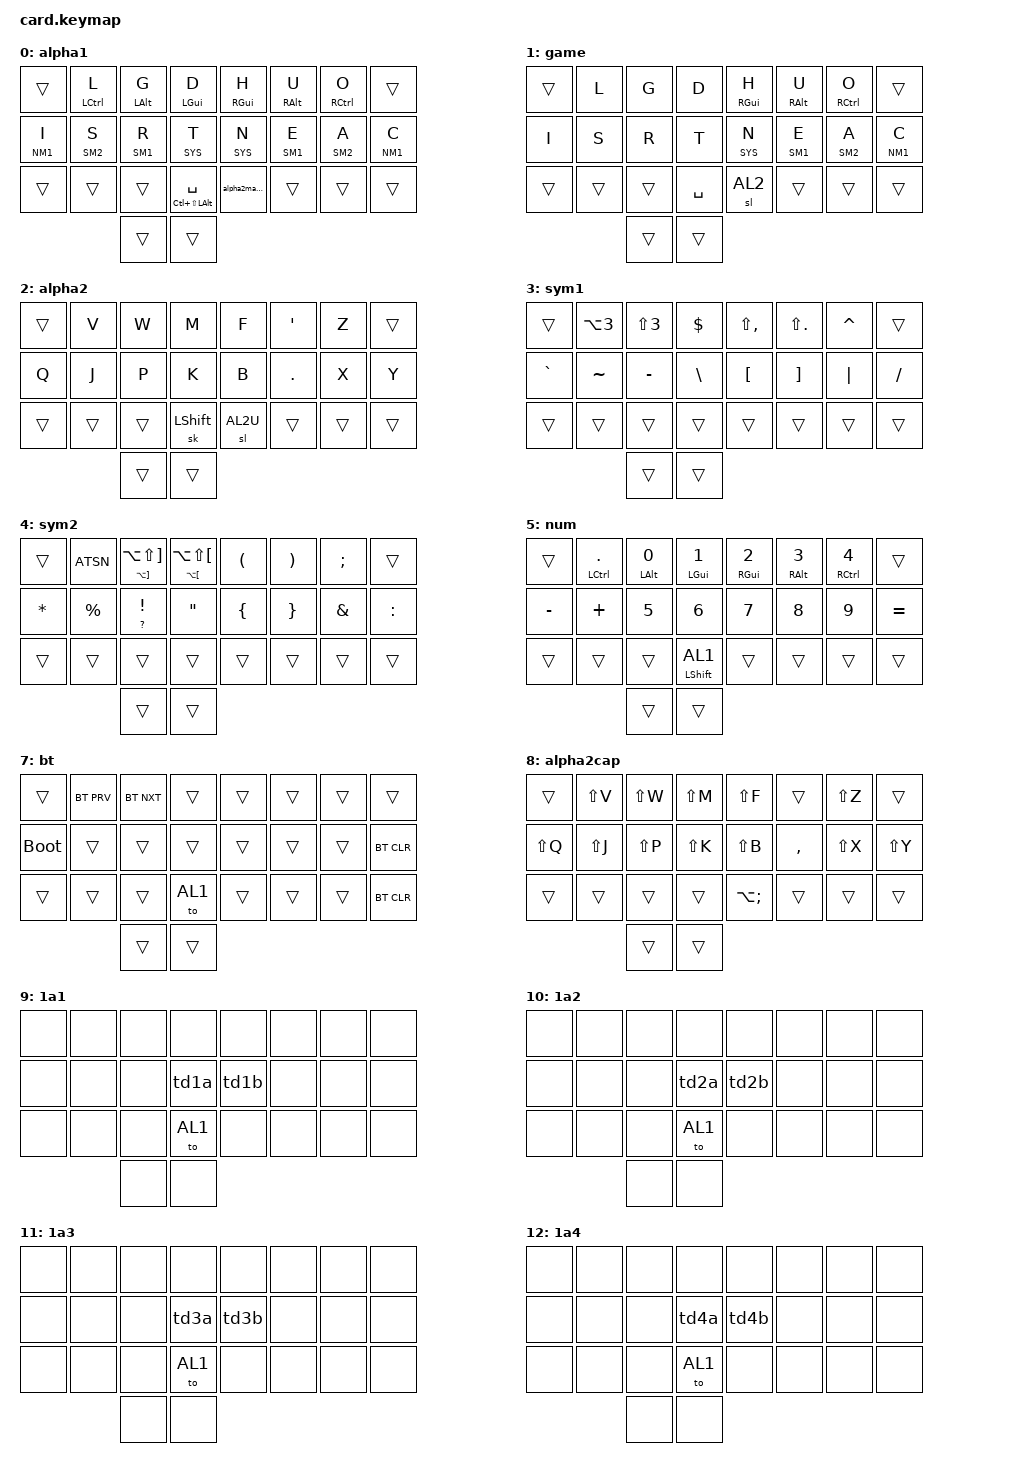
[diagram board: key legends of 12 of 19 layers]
/*
 * Copyright (c) 2020 The ZMK Contributors
 *
 * SPDX-License-Identifier: MIT
 */

#include <behaviors.dtsi>
#include <dt-bindings/zmk/keys.h>
#include <dt-bindings/zmk/bt.h>
#include <dt-bindings/zmk/mouse.h>



&mt {
    tapping-term-ms = <201>;
    flavor = "tap-preferred";
 };
&sk {
     release-after-ms = <2000>;
     quick-release;
 };
 
/* Layers */
#define AL1 0
#define GM 1
#define AL2 2
#define AL2U 8
#define SM1 3
#define SM2 4	
#define NM1 5	
#define SYS 6
#define BT 7	




#define AF1 9	
#define AF2 10	
#define AF3 11	
#define AF4 12	
#define AF5 13	
#define AF6 14	
#define AF7 15	
#define AF8 16	
#define AF9 17	
#define AF10 18	

/ { 
    combos {
        compatible = "zmk,combos";
        combo_game {
            timeout-ms = <30>;
	    key-positions = <2 3 4 5>;
            bindings = <&to GM>;
        };
        combo_1april {
            timeout-ms = <30>;
	    key-positions = <1 2 3>;
            bindings = <&to AF1>;
        };
        combo_sys {
            timeout-ms = <30>;
	    key-positions = <4 5 6>;
            bindings = <&to SYS>;
        };
        combo_caps {
            timeout-ms = <30>;
	    key-positions = <12 13 14>;
            bindings = <&caps_word>;
        };
        combo_bt  {
            timeout-ms = <10>;
            key-positions = <13 14>;
            bindings = <&to BT>;
	    layers = <SM1>; 
        };
        lalt {
            timeout-ms = <20>;
	    key-positions = <10 11>;
            bindings = <&kp LALT>; 
	    layers = <SYS>; 
        };
        lclk {
            timeout-ms = <20>;
	    key-positions = <12	13>;
            bindings = <&mkp LCLK>;
	    layers = <SYS>;
        };
        rclk {
            timeout-ms = <20>;
	    key-positions = <4 5>;
            bindings = <&mkp RCLK>;
	    layers = <SYS>;
        };


    };

    behaviors {
        hm: homerow_mods {
            compatible = "zmk,behavior-hold-tap";
            label = "HOMEROW_MODS";
            #binding-cells = <2>;
            tapping-term-ms = <300>;
            quick_tap_ms = <0>;
            flavor = "tap-preferred";
            bindings = <&kp>, <&kp>;
        };
        sr: shift_layer {
            compatible = "zmk,behavior-hold-tap";
            label = "SHIFT_LAYER";
            #binding-cells = <2>;
            tapping-term-ms = <300>;
            quick_tap_ms = <0>;
            flavor = "tap-preferred";
            bindings = <&kp>, <&to>;
	    retro-tap;
        };
        hl: homerow_layers {
            compatible = "zmk,behavior-hold-tap";
            label = "HOMEROW_LAYERS";
            #binding-cells = <2>;
            tapping-term-ms = <220>;
            quick_tap_ms = <0>;
            flavor = "tap-preferred";
            bindings = <&sl>, <&kp>;
        };
	td: tapdance {
            compatible = "zmk,behavior-hold-tap";
            label = "TAPDANCE";
            #binding-cells = <2>;
            tapping-term-ms = <190>;
            quick_tap_ms = <0>;
            flavor = "tap-preferred";
            bindings = <&kp>, <&kp>;
        };
	alpha2macro: behavior_macro_1 {
		compatible = "zmk,behavior-macro";
		label = "MACRO1";
		#binding-cells = <0>;
		bindings = < &sl AL2 >;
	};
	
	td1a: td1a {
            compatible = "zmk,behavior-tap-dance";
            label = "TD1A";
            #binding-cells = <0>;
            tapping-term-ms = <250>;
            bindings = <&sl AF2>, <&sl AF3>, <&sl AF4>;
        };
	td1b: td1b {
            compatible = "zmk,behavior-tap-dance";
            label = "TD1B";
            #binding-cells = <0>;
            tapping-term-ms = <250>;
            bindings = <&sl AF5>, <&sl AF6>, <&sl AF7>;
        };
	td2a: td2a {
            compatible = "zmk,behavior-tap-dance";
            label = "TD2A";
            #binding-cells = <0>;
            tapping-term-ms = <250>;
            bindings = <&kp A>, <&kp Y>, <&kp P>;
        };
	td2b: td2b {
            compatible = "zmk,behavior-tap-dance";
            label = "TD2B";
            #binding-cells = <0>;
            tapping-term-ms = <250>;
            bindings = <&kp E>, <&kp U>, <&kp X>;
        };
	td3a: td3a {
            compatible = "zmk,behavior-tap-dance";
            label = "TD3A";
            #binding-cells = <0>;
            tapping-term-ms = <250>;
            bindings = <&kp S>, <&kp V>, <&kp Q>;
        };
	td3b: td3b {
            compatible = "zmk,behavior-tap-dance";
            label = "TD3B";
            #binding-cells = <0>;
            tapping-term-ms = <250>;
            bindings = <&kp N>, <&kp R>, <&kp F>;
        };
	td4a: td4a {
            compatible = "zmk,behavior-tap-dance";
            label = "TD4A";
            #binding-cells = <0>;
            tapping-term-ms = <250>;
            bindings = <&kp K>, <&kp J>, <&kp Z>;
        };
	td4b: td4b {
            compatible = "zmk,behavior-tap-dance";
            label = "TD4B";
            #binding-cells = <0>;
            tapping-term-ms = <250>;
            bindings = <&kp H>, <&kp L>, <&kp W>;
        };
	td5a: td5a {
            compatible = "zmk,behavior-tap-dance";
            label = "TD5A";
            #binding-cells = <0>;
            tapping-term-ms = <250>;
            bindings = <&kp T>, <&kp M>, <&kp G>;
        };
	td5b: td5b {
            compatible = "zmk,behavior-tap-dance";
            label = "TD5B";
            #binding-cells = <0>;
            tapping-term-ms = <250>;
            bindings = <&kp I>, <&kp B>, <&kp Y>;
        };
	td6a: td6a {
            compatible = "zmk,behavior-tap-dance";
            label = "TD6A";
            #binding-cells = <0>;
            tapping-term-ms = <250>;
            bindings = <&kp O>, <&kp D>, <&kp QMARK>;
        };
	td6b: td6b {
            compatible = "zmk,behavior-tap-dance";
            label = "TD6B";
            #binding-cells = <0>;
            tapping-term-ms = <250>;
            bindings = <&kp BKSP>, <&kp RET>, <&kp TAB>;
        };
	td7a: td7a {
            compatible = "zmk,behavior-tap-dance";
            label = "TD7A";
            #binding-cells = <0>;
            tapping-term-ms = <250>;
            bindings = <&kp SPC>,<&kp ESC>, <&kp CAPS>;
        };
	td7b: td7b {
            compatible = "zmk,behavior-tap-dance";
            label = "TD7B";
            #binding-cells = <0>;
            tapping-term-ms = <250>;
            bindings = <&sl AF8>, <&sl AF9>, <&sl AF10>;
        };
	td8a: td8a {
            compatible = "zmk,behavior-tap-dance";
            label = "TD8A";
            #binding-cells = <0>;
            tapping-term-ms = <250>;
            bindings = <&kp N0>, <&kp N1>, <&kp N2>;
        };
	td8b: td8b {
            compatible = "zmk,behavior-tap-dance";
            label = "TD8B";
            #binding-cells = <0>;
            tapping-term-ms = <250>;
            bindings = <&kp N3>, <&kp N4>, <&kp N5>;
        };
	td9a: td9a {
            compatible = "zmk,behavior-tap-dance";
            label = "TD9A";
            #binding-cells = <0>;
            tapping-term-ms = <250>;
            bindings = <&kp N6>, <&kp N7>, <&kp N8>;
        };
	td9b: td9b {
            compatible = "zmk,behavior-tap-dance";
            label = "TD9B";
            #binding-cells = <0>;
            tapping-term-ms = <250>;
            bindings = <&kp N9>, <&kp MINUS>, <&kp DOT>;
        };
	td10a: td10a {
            compatible = "zmk,behavior-tap-dance";
            label = "TD10A";
            #binding-cells = <0>;
            tapping-term-ms = <250>;
            bindings = <&kp SQT>, <&kp DQT>, <&kp LBKT>;
        };
	td10b: td10b {
            compatible = "zmk,behavior-tap-dance";
            label = "TD11B";
            #binding-cells = <0>;
            tapping-term-ms = <250>;
            bindings = <&kp COMMA>, <&kp EXCL>, <&kp RBKT>;
        };
    };
       keymap {
                compatible = "zmk,keymap";
                
       		alpha1 {
		bindings = <
		&trans 		&hm LCTL L 	&hm LALT G 	&hm LGUI D		&hm RGUI H 	&hm RALT U    		&hm RCTL O	&trans  
		&hl NM1 I	&hl SM2 S	&hl SM1 R	&hl SYS T 	 	&hl SYS N    	&hl SM1 E   		&hl SM2 A 	&hl NM1 C
		&trans	 	&trans 		&trans 		&mt LC(LS(LALT)) SPC 	&alpha2macro	&trans 			&trans		&trans
								&trans	 		&trans
		>;
		};
       		game {
		bindings = <
		&trans 		&kp L 		&kp G 		&kp D			&hm RGUI H 	&hm RALT U    		&hm RCTL O	&trans  
		&kp I		&kp S		&kp R		&kp T 		 	&hl SYS N    	&hl SM1 E   		&hl SM2  A 	&hl NM1 C
		&trans	 	&trans 		&trans 		&kp SPC 		&sl AL2		&trans 			&trans		&trans
								&trans	 		&trans
		>;
		};
       		alpha2 {
		bindings = <
		&trans 	 	&kp V 		&kp W		&kp M	 	 	&kp F    	&kp SQT			&kp Z 		&trans
		&kp Q	 	&kp J 		&kp P		&kp K 			&kp B 		&kp DOT			&kp X		&kp Y 
		&trans	 	&trans 		&trans 		&sk LSHIFT 		&sl AL2U	&trans			&trans		&trans
								&trans	 		&trans
		>;
		};
		
       		sym1 {
		bindings = <
		&trans 		&kp LA(N3)   	&kp LS(N3)	&kp DLLR	    	&kp LS(COMMA)	&kp LS(DOT)		&kp CARET	&trans
		&kp GRAVE	&kp TILDE 	&kp MINUS      	&kp BSLH	 	&kp LBKT	&kp RBKT	 	&kp PIPE 	&kp SLASH
		&trans		&trans  	&trans		&trans  		&trans		&trans 			&trans  	&trans
							 	&trans		 	&trans
		>;
		};
		sym2 {
		bindings = <
		&trans		&kp ATSN	&td LA(RBKT) LA(LS(RBKT))	&td  LA(LBKT) LA(LS(LBKT))	&kp LPRN	&kp RPRN 	&kp SEMI 	&trans
		&kp STAR  	&kp PRCNT	&td QMARK EXCL       		&kp DQT   			&kp LBRC  	&kp RBRC	&kp AMPS	&kp COLON 
		&trans 		&trans 		&trans  			&trans 				&trans 		&trans 		&trans 		&trans   
						 				&trans				&trans

		>;
		};

		num {
		bindings = <
		&trans		&hm LCTL DOT 	&hm LALT N0	&hm LGUI N1 		&hm RGUI N2 	&hm RALT N3		&hm RCTL N4	&trans
		&kp MINUS	&kp PLUS 	&kp N5		&kp N6			&kp N7		&kp N8			&kp N9   	&kp EQUAL
		&trans  	&trans 		&trans		&sr LSHIFT AL1 		&trans 		&trans 			&trans  	&trans 
								&trans	 	 	&trans
		>;
		};

		sys {
		bindings = <
		&trans		 	&kp ESC			&kp LC(LS(TAB)) 	&kp RC(TAB)		&td LG(V) LG(C) 	&kp UP 		&td Q BKSP 			&trans
		&td LG(GRAVE) TAB	&td HOME DEL		&td END LG(LBKT) 	&kp LG(RBKT)		&td TAB LEFT  		&kp DOWN 	&td  LC(LG(LS(N4))) RIGHT 	&kp RET 
		&trans 			&trans 		 	&trans			&sr LSHIFT AL1 		&kp RGUI		&trans 		&trans				&trans 	   
									 		&trans	 		&trans
		>;
		};

		bt {
		bindings = <
		&trans		&bt BT_PRV	&bt BT_NXT	&trans 			&trans 	&trans	&trans	&trans
		&bootloader  	&trans 		&trans 		&trans 			&trans 	&trans 	&trans	&bt BT_CLR
		&trans 	 	&trans 		&trans		&to AL1			&trans  &trans  &trans 	&bt BT_CLR
						 		&trans			&trans
		>;
		};

       		alpha2cap {
		bindings = <
		&trans 	 	&kp LS(V)	&kp LS(W)	&kp LS(M) 	 	&kp LS(F)    	&trans		&kp LS(Z)	&trans 
		&kp LS(Q) 	&kp LS(J) 	&kp LS(P)	&kp LS(K)		&kp LS(B)	&kp COMMA	&kp LS(X)	&kp LS(Y) 
		&trans	 	&trans 		&trans 		&trans 			&kp LA(SEMI)	&trans		&trans		&trans
								&trans	 		&trans
		>;
		};








       		1a1 {
		bindings = <
		&none 	 	&none		&none 		&none			&none		&none		&none		&none
		&none 	 	&none		&none 		&td1a			&td1b		&none		&none		&none
		&none 	 	&none		&none 		&to AL1			&none		&none		&none		&none
								&none	 		&none
		>;
		};
       		1a2 {
		bindings = <
		&none 	 	&none		&none 		&none			&none		&none		&none		&none
		&none 	 	&none		&none 		&td2a 			&td2b		&none		&none		&none
		&none 	 	&none		&none 		&to AL1			&none		&none		&none		&none
								&none	 		&none
		>;
		};
       		1a3 {
		bindings = <
		&none 	 	&none		&none 		&none			&none		&none		&none		&none
		&none 	 	&none		&none 		&td3a			&td3b		&none		&none		&none
		&none 	 	&none		&none 		&to AL1			&none		&none		&none		&none
								&none	 		&none
		>;
		};
       		1a4 {
		bindings = <
		&none 	 	&none		&none 		&none			&none		&none		&none		&none
		&none 	 	&none		&none 		&td4a			&td4b		&none		&none		&none
		&none 	 	&none		&none 		&to AL1			&none		&none		&none		&none
								&none	 		&none
		>;
		};
       		1a5 {
		bindings = <
		&none 	 	&none		&none 		&none			&none		&none		&none		&none
		&none 	 	&none		&none 		&td5a			&td5b		&none		&none		&none
		&none 	 	&none		&none 		&to AL1			&none		&none		&none		&none
								&none	 		&none
		>;
		};
       		1a6 {
		bindings = <
		&none 	 	&none		&none 		&none			&none		&none		&none		&none
		&none 	 	&none		&none 		&td6a			&td6b		&none		&none		&none
		&none 	 	&none		&none 		&to AL1			&none		&none		&none		&none
								&none	 		&none
		>;
		};
       		1a7 {
		bindings = <
		&none 	 	&none		&none 		&none			&none		&none		&none		&none
		&none 	 	&none		&none 		&td7a			&td7b		&none		&none		&none
		&none 	 	&none		&none 		&to AL1			&none		&none		&none		&none
								&none	 		&none
		>;
		};
       		1a8 {
		bindings = <
		&none 	 	&none		&none 		&none			&none		&none		&none		&none
		&none 	 	&none		&none 		&td8a			&td8b		&none		&none		&none
		&none 	 	&none		&none 		&to AL1			&none		&none		&none		&none
								&none	 		&none
		>;
		};
       		1a9 {
		bindings = <
		&none 	 	&none		&none 		&none			&none		&none		&none		&none
		&none 	 	&none		&none 		&td9a			&td9b		&none		&none		&none
		&none 	 	&none		&none 		&to AL1			&none		&none		&none		&none
								&none	 		&none
		>;
		};
       		1a10 {
		bindings = <
		&none 	 	&none		&none 		&none			&none		&none		&none		&none
		&none 	 	&none		&none 		&td10a			&td10b		&none		&none		&none
		&none 	 	&none		&none 		&to AL1			&none		&none		&none		&none
								&none	 		&none
		>;
		};
        
	};
};
